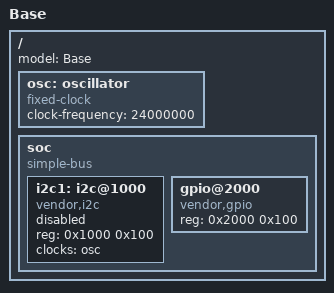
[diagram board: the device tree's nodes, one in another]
/dts-v1/;
/ {
	#address-cells = <1>;
	#size-cells = <1>;
	model = "Base";

	osc: oscillator {
		compatible = "fixed-clock";
		#clock-cells = <0>;
		clock-frequency = <24000000>;
	};

	soc: soc {
		compatible = "simple-bus";
		#address-cells = <1>;
		#size-cells = <1>;
		ranges;

		i2c1: i2c@1000 {
			compatible = "vendor,i2c";
			reg = <0x1000 0x100>;
			#address-cells = <1>;
			#size-cells = <0>;
			clocks = <&osc>;
			status = "disabled";
		};

		gpio@2000 {
			compatible = "vendor,gpio";
			reg = <0x2000 0x100>;
		};
	};
};
